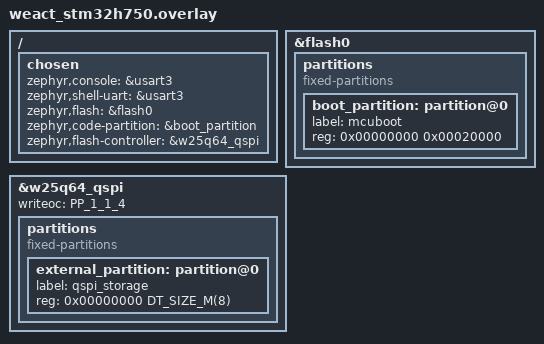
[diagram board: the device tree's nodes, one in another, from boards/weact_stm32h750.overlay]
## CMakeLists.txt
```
# SPDX-License-Identifier: Apache-2.0

cmake_minimum_required(VERSION 3.20.0)

# 指定自定义板级路径
set(BOARD_ROOT "${CMAKE_CURRENT_LIST_DIR}/..")

find_package(Zephyr REQUIRED HINTS $ENV{ZEPHYR_BASE})
project(hello_qspi_flash)

target_sources(app PRIVATE src/main.c)
```

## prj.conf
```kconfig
# CONFIG_I2C=y
CONFIG_SPI=y
CONFIG_MAIN_STACK_SIZE=8196
CONFIG_IDLE_STACK_SIZE=4096
CONFIG_SYSTEM_WORKQUEUE_STACK_SIZE=8196
# CONFIG_INIT_STACKS is not set
CONFIG_HW_STACK_PROTECTION=y
CONFIG_GPIO=y
CONFIG_LOG=y
CONFIG_CONSOLE=y
CONFIG_ISR_STACK_SIZE=8196
CONFIG_PRIVILEGED_STACK_SIZE=8196
CONFIG_ARM_MPU=y
# CONFIG_THREAD_MONITOR is not set
# CONFIG_THREAD_NAME is not set
# CONFIG_DEVICE_DT_METADATA is not set
CONFIG_DEBUG=y
CONFIG_FLASH=y
CONFIG_PRINTK=y
CONFIG_UART_CONSOLE=y
# CONFIG_DISPLAY=y
CONFIG_FLASH_JESD216_API=y
CONFIG_FLASH_SHELL=y
CONFIG_FLASH_SHELL_TEST_COMMANDS=y
CONFIG_GPIO_SHELL=y
# CONFIG_I2C_SHELL=y
# CONFIG_SDHC=y
CONFIG_SPI_SHELL=y
# CONFIG_COMMON_LIBC_REMOVE is not set
CONFIG_CRC=y
# CONFIG_FILE_SYSTEM=y
# CONFIG_FILE_SYSTEM_MKFS=y
# CONFIG_FAT_FILESYSTEM_ELM=y
CONFIG_SHELL=y
CONFIG_FLASH_MAP=y
CONFIG_FLASH_MAP_SHELL=y
# CONFIG_FLASH_MAP_LABELS is not set
```

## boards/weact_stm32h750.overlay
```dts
/* MCUBoot overlay for WeAct STM32H750 board
 * - Place MCUBoot in internal flash (128KB)
 * - Define external QSPI slots for Direct-XIP
 */

/ {
	/* For MCUBoot itself, link to internal flash */
	chosen {
		zephyr,console = &usart3;
        zephyr,shell-uart = &usart3;
		zephyr,flash = &flash0;
		zephyr,code-partition = &boot_partition;
		zephyr,flash-controller = &w25q64_qspi;
	};
};

/* Internal Flash (128KB) holds MCUBoot */
&flash0 {
	partitions {
		compatible = "fixed-partitions";
		#address-cells = <1>;
		#size-cells = <1>;

		boot_partition: partition@0 {
			label = "mcuboot";
			reg = <0x00000000 0x00020000>; /* 128KB */
		};
	};
};

&w25q64_qspi {
	// W25Q64不支持1-4-4模式，改为1-1-4模式（指单线指令，单线地址，四线数据，1-4-4类似）
    writeoc = "PP_1_1_4";

	partitions {
		compatible = "fixed-partitions";
		#address-cells = <1>;
		#size-cells = <1>;

		external_partition: partition@0 {
			label = "qspi_storage";
			reg = <0x00000000 DT_SIZE_M(8)>;
		};
	};
};

/* Remove the board's default MCUboot slots from external QSPI */
/delete-node/ &slot0_partition;
/delete-node/ &slot1_partition;
/delete-node/ &scratch_partition;
```

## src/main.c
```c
/*
 * Copyright (c) 2016 Intel Corporation.
 *
 * SPDX-License-Identifier: Apache-2.0
 */

#include <zephyr/kernel.h>
#include <zephyr/drivers/flash.h>
#include <zephyr/device.h>
#include <zephyr/devicetree.h>
#include <stdio.h>
#include <string.h>

#define SPI_FLASH_TEST_REGION_OFFSET 0X00080000 // DT_REG_ADDR(DT_NODELABEL(scratch_partition))
#define SPI_FLASH_SECTOR_SIZE        4096

#define SPI_FLASH_MULTI_SECTOR_TEST

#define SPI_FLASH_COMPAT st_stm32_qspi_nor

const uint8_t erased[] = {0xff, 0xff, 0xff, 0xff};

void single_sector_test(const struct device *flash_dev)
{
	const uint8_t expected[] = {0x55, 0xaa, 0x66, 0x99};
	const size_t len = sizeof(expected);
	uint8_t buf[sizeof(expected)];
	int rc;

	printf("\nPerform test on single sector");
	/* Write protection needs to be disabled before each write or
	 * erase, since the flash component turns on write protection
	 * automatically after completion of write and erase
	 * operations.
	 */
	printf("\nTest 1: Flash erase\n");

	/* Full flash erase if SPI_FLASH_TEST_REGION_OFFSET = 0 and
	 * SPI_FLASH_SECTOR_SIZE = flash size
	 */
	rc = flash_erase(flash_dev, SPI_FLASH_TEST_REGION_OFFSET, SPI_FLASH_SECTOR_SIZE);
	if (rc != 0) {
		printf("Flash erase failed! %d\n", rc);
	} else {
		/* Check erased pattern */
		memset(buf, 0, len);
		rc = flash_read(flash_dev, SPI_FLASH_TEST_REGION_OFFSET, buf, len);
		if (rc != 0) {
			printf("Flash read failed! %d\n", rc);
			return;
		}
		if (memcmp(erased, buf, len) != 0) {
			printf("Flash erase failed at offset 0x%x got 0x%x\n",
			       SPI_FLASH_TEST_REGION_OFFSET, *(uint32_t *)buf);
			return;
		}
		printf("Flash erase succeeded!\n");
	}
	printf("\nTest 2: Flash write\n");

	printf("Attempting to write %zu bytes\n", len);
	rc = flash_write(flash_dev, SPI_FLASH_TEST_REGION_OFFSET, expected, len);
	if (rc != 0) {
		printf("Flash write failed! %d\n", rc);
		return;
	}

	memset(buf, 0, len);
	rc = flash_read(flash_dev, SPI_FLASH_TEST_REGION_OFFSET, buf, len);
	if (rc != 0) {
		printf("Flash read failed! %d\n", rc);
		return;
	}

	if (memcmp(expected, buf, len) == 0) {
		printf("Data read matches data written. Good!!\n");
	} else {
		const uint8_t *wp = expected;
		const uint8_t *rp = buf;
		const uint8_t *rpe = rp + len;

		printf("Data read does not match data written!!\n");
		while (rp < rpe) {
			printf("%08x wrote %02x read %02x %s\n",
			       (uint32_t)(SPI_FLASH_TEST_REGION_OFFSET + (rp - buf)), *wp, *rp,
			       (*rp == *wp) ? "match" : "MISMATCH");
			++rp;
			++wp;
		}
	}
}

#if defined SPI_FLASH_MULTI_SECTOR_TEST
void multi_sector_test(const struct device *flash_dev)
{
	const uint8_t expected[] = {0x55, 0xaa, 0x66, 0x99};
	const size_t len = sizeof(expected);
	uint8_t buf[sizeof(expected)];
	int rc;

	printf("\nPerform test on multiple consecutive sectors");

	/* Write protection needs to be disabled before each write or
	 * erase, since the flash component turns on write protection
	 * automatically after completion of write and erase
	 * operations.
	 */
	printf("\nTest 1: Flash erase\n");

	/* Full flash erase if SPI_FLASH_TEST_REGION_OFFSET = 0 and
	 * SPI_FLASH_SECTOR_SIZE = flash size
	 * Erase 2 sectors for check for erase of consequtive sectors
	 */
	rc = flash_erase(flash_dev, SPI_FLASH_TEST_REGION_OFFSET, SPI_FLASH_SECTOR_SIZE * 2);
	if (rc != 0) {
		printf("Flash erase failed! %d\n", rc);
	} else {
		/* Read the content and check for erased */
		memset(buf, 0, len);
		size_t offs = SPI_FLASH_TEST_REGION_OFFSET;

		while (offs < SPI_FLASH_TEST_REGION_OFFSET + 2 * SPI_FLASH_SECTOR_SIZE) {
			rc = flash_read(flash_dev, offs, buf, len);
			if (rc != 0) {
				printf("Flash read failed! %d\n", rc);
				return;
			}
			if (memcmp(erased, buf, len) != 0) {
				printf("Flash erase failed at offset 0x%x got 0x%x\n", offs,
				       *(uint32_t *)buf);
				return;
			}
			offs += SPI_FLASH_SECTOR_SIZE;
		}
		printf("Flash erase succeeded!\n");
	}

	printf("\nTest 2: Flash write\n");

	size_t offs = SPI_FLASH_TEST_REGION_OFFSET;

	while (offs < SPI_FLASH_TEST_REGION_OFFSET + 2 * SPI_FLASH_SECTOR_SIZE) {
		printf("Attempting to write %zu bytes at offset 0x%x\n", len, offs);
		rc = flash_write(flash_dev, offs, expected, len);
		if (rc != 0) {
			printf("Flash write failed! %d\n", rc);
			return;
		}

		memset(buf, 0, len);
		rc = flash_read(flash_dev, offs, buf, len);
		if (rc != 0) {
			printf("Flash read failed! %d\n", rc);
			return;
		}

		if (memcmp(expected, buf, len) == 0) {
			printf("Data read matches data written. Good!!\n");
		} else {
			const uint8_t *wp = expected;
			const uint8_t *rp = buf;
			const uint8_t *rpe = rp + len;

			printf("Data read does not match data written!!\n");
			while (rp < rpe) {
				printf("%08x wrote %02x read %02x %s\n",
				       (uint32_t)(offs + (rp - buf)), *wp, *rp,
				       (*rp == *wp) ? "match" : "MISMATCH");
				++rp;
				++wp;
			}
		}
		offs += SPI_FLASH_SECTOR_SIZE;
	}
}
#endif

int test_qspi_flash(void)
{
	const struct device *flash_dev = DEVICE_DT_GET_ONE(SPI_FLASH_COMPAT);

	if (!device_is_ready(flash_dev)) {
		printk("%s: device not ready.\n", flash_dev->name);
		return 0;
	}

	uint8_t id;
	/* Write protection is typically handled by the driver (WREN); no extra API needed here. */
	flash_read_jedec_id(flash_dev, &id);
	printf("\n%s SPI flash ID: 0x%02x\n", flash_dev->name, id);

	printf("\n%s SPI flash testing\n", flash_dev->name);
	printf("==========================\n");
	printf("Test region base: 0x%08x, sector size: %u\n",
	       (unsigned int)SPI_FLASH_TEST_REGION_OFFSET, (unsigned int)SPI_FLASH_SECTOR_SIZE);

	single_sector_test(flash_dev);
#if defined SPI_FLASH_MULTI_SECTOR_TEST
	multi_sector_test(flash_dev);
#endif
	return 0;
}

int main(void)
{
	test_qspi_flash();
	return 0;
}

// K_THREAD_DEFINE(test_qspi_flash_id, 4096, test_qspi_flash, NULL, NULL, NULL, 10, 0, 0);
```
